# RS14100 register map
File version: 1.0
CPU: CM4 r0p1, little endian, MPU, FPU, 4 interrupt priority bits
Registers are 32-bit, read-write, reset 0x0 unless marked. A register's access mark holds for its fields unless they carry their own. Offsets are from the block's base; [hi:lo] are bit positions.

## MCU_WDT — A dedicated window watch dog timer for MCU applications
Base 0x24048300
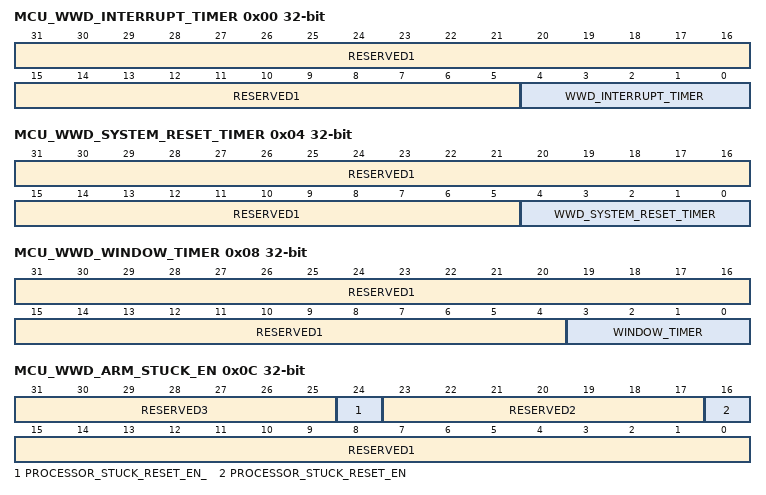
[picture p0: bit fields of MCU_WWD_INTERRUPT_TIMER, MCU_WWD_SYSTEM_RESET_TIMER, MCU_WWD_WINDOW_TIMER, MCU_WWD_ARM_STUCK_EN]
0x00 MCU_WWD_INTERRUPT_TIMER — WATCHDOG interrupt timer register
  [31:5] RESERVED1 ro — reser
  [4:0] WWD_INTERRUPT_TIMER — Watchdog Timer programming values
0x04 MCU_WWD_SYSTEM_RESET_TIMER — MCU watchdog system reset register
  [31:5] RESERVED1 ro — reser
  [4:0] WWD_SYSTEM_RESET_TIMER — Watch dog soc reset delay timer programming values
0x08 MCU_WWD_WINDOW_TIMER — watchdog window timer register
  [31:4] RESERVED1 ro — reser
  [3:0] WINDOW_TIMER — watchdog window timer
0x0C MCU_WWD_ARM_STUCK_EN — watchdog arm stuck enable register
  [31:25] RESERVED3 ro — reser
  [24] PROCESSOR_STUCK_RESET_EN_ ro — Read signal for processor stuck reset enable
  [23:17] RESERVED2 ro — reser
  [16] PROCESSOR_STUCK_RESET_EN wo — Enable to reset M4 core on seeing LOCKUP signal
  [15:0] RESERVED1 ro — reser
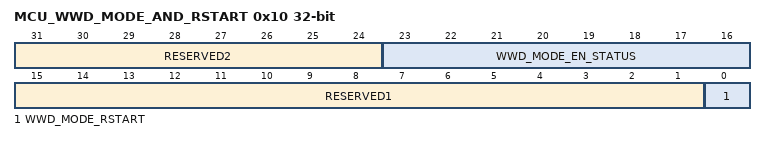
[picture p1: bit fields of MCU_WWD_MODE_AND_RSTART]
0x10 MCU_WWD_MODE_AND_RSTART — WATCHDOG mode and restart register
  [31:24] RESERVED2 ro — reser
  [23:16] WWD_MODE_EN_STATUS — Watchdog timer mode
  [15:1] RESERVED1 ro — reser
  [0] WWD_MODE_RSTART — restart pulse to restart watchdog timer
0x18 MCU_WWD_KEY_ENABLE reset 0xFFFFFFFF — watchdog key enable register
  [31:0] WWD_KEY_ENABLE wo — enable access to program Watch dog registers

## MCU_Calender — The MCU calender acts as RTC with time in seconds, minutes, hours, days, months, years and centuries
Base 0x2404821C
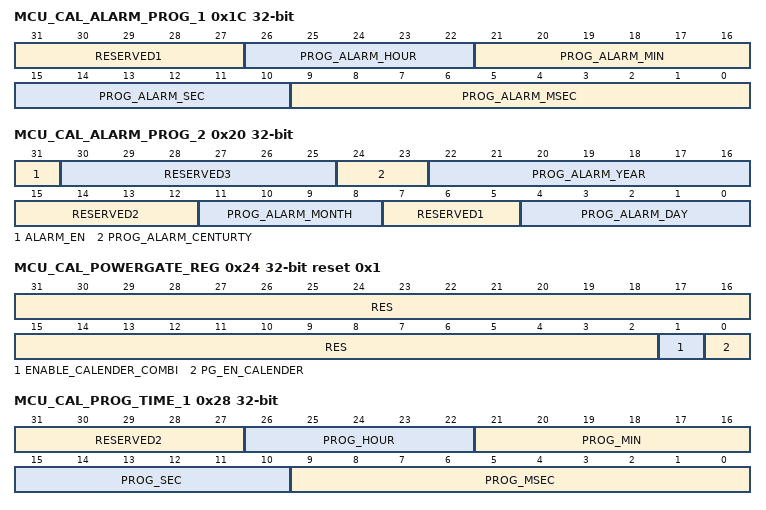
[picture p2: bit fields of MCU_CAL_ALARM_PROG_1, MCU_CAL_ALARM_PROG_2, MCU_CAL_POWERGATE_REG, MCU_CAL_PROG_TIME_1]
0x1C MCU_CAL_ALARM_PROG_1 — MCU calender alarm prog register 1
  [31:27] RESERVED1 ro — reser
  [26:22] PROG_ALARM_HOUR — hours value of alarm time
  [21:16] PROG_ALARM_MIN — mins value of alarm time
  [15:10] PROG_ALARM_SEC — seconds value of alarm time
  [9:0] PROG_ALARM_MSEC — milli seconds value of alarm time
0x20 MCU_CAL_ALARM_PROG_2 — MCU calender alarm prog register 2
  [31] ALARM_EN — alarm function enable for calendar
  [30:25] RESERVED3 ro — reser
  [24:23] PROG_ALARM_CENTURTY — century count in alarm time
  [22:16] PROG_ALARM_YEAR — year count in alarm time 0 - 99
  [15:12] RESERVED2 ro — reser
  [11:8] PROG_ALARM_MONTH — month count in alarm time
  [7:5] RESERVED1 ro — reser
  [4:0] PROG_ALARM_DAY — day count in alarm time 1-31
0x24 MCU_CAL_POWERGATE_REG reset 0x1 — MCU calender powergate register
  [31:2] RES ro — reser
  [1] ENABLE_CALENDER_COMBI — Enable calender combitional logic block
  [0] PG_EN_CALENDER — Start calender block
0x28 MCU_CAL_PROG_TIME_1 — MCU calendar prog time 1 register
  [31:27] RESERVED2 ro — reser
  [26:22] PROG_HOUR — hours value to be programmed to real time in calendar when pro_time_trig is 1
  [21:16] PROG_MIN — minutes value to be programmed to real time in calendar when pro_time_trig is 1
  [15:10] PROG_SEC — seconds value to be programmed to real time in calendar when pro_time_trig is 1
  [9:0] PROG_MSEC — Milli seconds value to be programmed to real time in calendar when pro_time_trig is 1
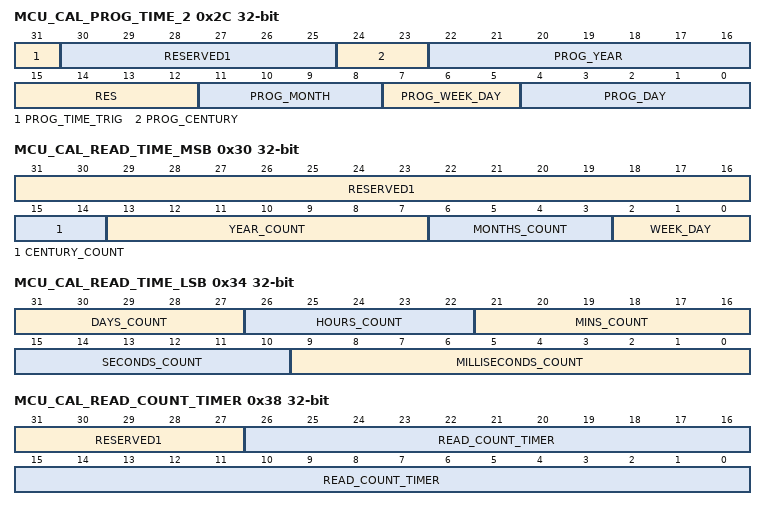
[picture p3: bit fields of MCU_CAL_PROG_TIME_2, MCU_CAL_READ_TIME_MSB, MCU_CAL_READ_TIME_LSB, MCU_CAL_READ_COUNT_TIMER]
0x2C MCU_CAL_PROG_TIME_2 — MCU calendar prog time 2 register
  [31] PROG_TIME_TRIG — load the programmed to the real time in calendar block
  [30:25] RESERVED1 ro — reser
  [24:23] PROG_CENTURY — century value to be programmed to real time in calendar when pro_time_trig is 1
  [22:16] PROG_YEAR — year value to be programmed to real time in calendar when pro_time_trig is 1
  [15:12] RES ro — reser
  [11:8] PROG_MONTH — month value to be programmed to real time in calendar when pro_time_trig is 1
  [7:5] PROG_WEEK_DAY — program which week day it is
  [4:0] PROG_DAY — day count value to be programmed to real time in calendar when pro_time_trig is 1
0x30 MCU_CAL_READ_TIME_MSB — MCU calendar read time msb
  [31:16] RESERVED1 ro — reser
  [15:14] CENTURY_COUNT
  [13:7] YEAR_COUNT — years count
  [6:3] MONTHS_COUNT
  [2:0] WEEK_DAY
0x34 MCU_CAL_READ_TIME_LSB — MCU calendar read time lsb
  [31:27] DAYS_COUNT, [26:22] HOURS_COUNT, [21:16] MINS_COUNT, [15:10] SECONDS_COUNT, [9:0] MILLISECONDS_COUNT
0x38 MCU_CAL_READ_COUNT_TIMER — MCU calendar read count timer
  [31:27] RESERVED1 ro — reser
  [26:0] READ_COUNT_TIMER — Read timer which increments by time period value to reach to count milliseconds
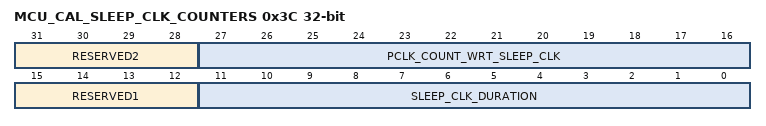
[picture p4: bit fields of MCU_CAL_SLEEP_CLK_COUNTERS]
0x3C MCU_CAL_SLEEP_CLK_COUNTERS — MCU calendar sleep clock counter
  [31:28] RESERVED2 ro — reser
  [27:16] PCLK_COUNT_WRT_SLEEP_CLK — no. of APB clks in 1 sleep clock duration
  [15:12] RESERVED1 ro — reser
  [11:0] SLEEP_CLK_DURATION — No of sleep clks with respect to APB clock so far from the posedge of sleep clk
0x40 MCU_CAL_KEY_EANBLE reset 0xFFFFFFFF — MCU calendar key enable
  [31:0] RTC_KEY — enable access to program Watch dog registers
